# RTI_SMS_LITE_TIFS_WDT_RTI_44135000h register map
Vendor: Texas Instruments
Peripheral module from a debugger description file (folder am62L).
Registers are 32-bit, read-write, reset 0x0 unless marked. A register's access mark holds for its fields unless they carry their own. Offsets are as the file gives them; lines under a group give offsets from that group; [hi:lo] are bit positions; {n}, {i} and the like mark numbered series; 'fields as' and 'values as' point back to an identical list; <NAME> marks a mode.

## SMS_LITE_TIFS_WDT_RTI
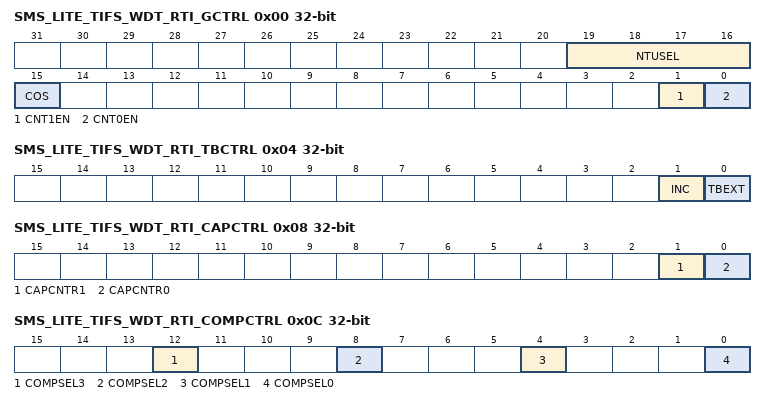
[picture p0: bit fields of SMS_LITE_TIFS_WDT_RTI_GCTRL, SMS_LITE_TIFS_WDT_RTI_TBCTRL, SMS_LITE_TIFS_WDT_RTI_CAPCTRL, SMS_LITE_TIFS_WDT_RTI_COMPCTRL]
0x00 SMS_LITE_TIFS_WDT_RTI_GCTRL
  [19:16] NTUSEL — These bits determine which NTU input signal is used as external timebase. There are up to four inputs supported with four valid selection combinations. Any invalid selection value written to the NTUSEL bit-field will result in a TIED LOW being used as the NTU signal. The NTU signal will also be TIED LOW in case of a single-bit flip as it will result in an invalid combination of NTUSEL. User and privilege mode (read): 0000 = NTU0 0101 = NTU1 1010 = NTU2 1111 = NTU3 other = tied to '0' Privilege mode (write): 0000 = NTU0 0101 = NTU1 1010 = NTU2 1111 = NTU3 other = tied to '0' Reset Source: sms_custom_rst_mod_g_rst_n
  [15] COS — This bit determines if both counters are stopped when the device goes into debug mode or if they continue counting. User and privilege mode (read): 0 = counters are stopped while in debug mode 1 = counters are running while in debug mode Privilege mode (write): 0 = stop counters in debug mode 1 = continue counting in debug mode Reset Source: sms_custom_rst_mod_g_rst_n
  [1] CNT1EN — The CNT1EN bit starts and stops the operation of counter block 1 (UC1 and FRC1). User and privilege mode (read): 0 = counters are stopped 1 = counters are running Privilege mode (write): 0 = stop counters 1 = start counters Reset Source: sms_custom_rst_mod_g_rst_n
  [0] CNT0EN — The CNT0EN bit starts and stops the operation of counter block 0 (UC0 and FRC0). User and privilege mode (read): 0 = counters are stopped 1 = counters are running Privilege mode (write): 0 = stop counters 1 = start counters Reset Source: sms_custom_rst_mod_g_rst_n
0x04 SMS_LITE_TIFS_WDT_RTI_TBCTRL
  [1] INC — This bit determines wether the Free Running Counter 0 is automatically incremented if a failing clock on the NTUx signal is detected. User and privilege mode (read): 0 = FRC0 will not be incremented 1 = FRC0 will be incremented Privilege mode (write): 0 = Do not increment FRC0 on failing external clock 1 = Increment FRC0 on failing external clock Reset Source: sms_custom_rst_mod_g_rst_n
  [0] TBEXT — The Timebase External bit selects whether the Free Running Counter 0 is clocked by the internal Up Counter 0 or from the external signal NTUx. Since setting the TBEXT bit to 1 resets Up Counter 0, Free Running Counter 0 will not be incremented in this occurence. The only source which is able to increment Free Running Counter 0 is NTUx. When the Timebase Supervisor circuit detects a missing clockedge, then the TBEXT bit is reset. The selection if the external signal should be used, can only be done by software. User and privilege mode (read): 0 = UC0 clocks FRC0 1 = NTUx clocks FRC0 Privilege mode (write): 0 = MUX is switched to internal UC0 clocking scheme 1 = MUX is switched to external NTUx clocking scheme Reset Source: sms_custom_rst_mod_g_rst_n
0x08 SMS_LITE_TIFS_WDT_RTI_CAPCTRL
  [1] CAPCNTR1 — This bit determines, which external interrupt source triggers a capture event of both UC1 and FRC1. User and privilege mode (read): 0 = capture event is triggered by Capture Event Source 0 1 = capture event is triggered by Capture Event Source 1 Privilege mode (write): 0 = enable capture event triggered by Capture Event Source 0 1 = enable capture event triggered by Capture Event Source 1 Reset Source: sms_custom_rst_mod_g_rst_n
  [0] CAPCNTR0 — This bit determines, which external interrupt source triggers a capture event of both UC0 and FRC0. User and privilege mode (read): 0 = capture event is triggered by Capture Event Source 0 1 = capture event is triggered by Capture Event Source 1 Privilege mode (write): 0 = enable capture event triggered by Capture Event Source 0 1 = enable capture event triggered by Capture Event Source 1 Reset Source: sms_custom_rst_mod_g_rst_n
0x0C SMS_LITE_TIFS_WDT_RTI_COMPCTRL
  [12] COMPSEL3 — This bit determines the counter with which the compare value hold in compare register 3 is compared. User and privilege mode (read): 0 = value will be compared with FRC 0 1 = value will be compared with FRC 1 Privilege mode (write): 0 = enable compare with FRC 0 1 = enable compare with FRC 1 Reset Source: sms_custom_rst_mod_g_rst_n
  [8] COMPSEL2 — This bit determines the counter with which the compare value hold in compare register 2 is compared. User and privilege mode (read): 0 = value will be compared with FRC 0 1 = value will be compared with FRC 1 Privilege mode (write): 0 = enable compare with FRC 0 1 = enable compare with FRC 1 Reset Source: sms_custom_rst_mod_g_rst_n
  [4] COMPSEL1 — This bit determines the counter with which the compare value hold in compare register 1 is compared.User and privilege mode (read): 0 = value will be compared with FRC 0 1 = value will be compared with FRC 1 Privilege mode (write): 0 = enable compare with FRC 0 1 = enable compare with FRC 1 Reset Source: sms_custom_rst_mod_g_rst_n
  [0] COMPSEL0 — This bit determines the counter with which the compare value hold in compare register 0 is compared. User and privilege mode (read): 0 = value will be compared with FRC 0 1 = value will be compared with FRC 1 Privilege mode (write): 0 = enable compare with FRC 0 1 = enable compare with FRC 1 Reset Source: sms_custom_rst_mod_g_rst_n
0x10 SMS_LITE_TIFS_WDT_RTI_FRC0
  [31:0] FRC0 — This registers holds the current value of the Free Running Counter 0 and will be updated continuously. User and privilege mode (read): current value of the counter Privilege mode (write): The counter can be preset by Writing to this register. The counter increments then from this written value upwards. Note: Presetting counters If counters have to be preset, they have to be stopped from counting in the RTIGCTRL register in order to ensure consistency between RTIUC0 and RTIFRC0. Reset Source: sms_custom_rst_mod_g_rst_n
0x14 SMS_LITE_TIFS_WDT_RTI_UC0
  [31:0] UC0 — This registers holds the current value of the Up Counter 0 and prescales the RTI clock. It will be only updated by a previous read of Free Running Counter 0. This gives effectively a 64 bit read of both counters, without having the problem of a counter being updated between two consecutive reads on Up Counter 0 and Free Running Counter 0. User and privilege mode (read): value of the counter when the Free Running Counter 0 was read Privilege mode (write): the counter can be preset by Writing to this register. The counter increments then from this written value upwards. Note: Presetting counters If counters have to be preset, they have to be stopped from counting in the RTIGCTRL register in order to ensure consistency between RTIUC0 and RTIFRC0. Note: Preset value concern If the preset value is bigger than the compare value stored in register RTICPUC0 then it can take a long time until a compare matches, since RTIUC0 has to count up until it overflows. Reset Source: sms_custom_rst_mod_g_rst_n
0x18 SMS_LITE_TIFS_WDT_RTI_CPUC0
  [31:0] CPUC0 — This registers holds the compare value, which is compared with the Up Counter 0. When the compare matches, Free Running counter 0 is incremented. The Up Counter is set to zero when the counter value matches the CPUC0 value. The value set in this prescales the RTI clock. If CPUC0 = 0: fFRC0 = R-----T---I---C----L----K-- 232 If CPUC0 0: fFRC0 = ----R----T----I--C-----L---K------- CPUC0 + 1 User and privilege mode (read): current compare value Privilege mode (write when TBEXT = 0): the compare value is updated Privilege mode (write when TBEXT = 1): the compare value is not changed Reset Source: sms_custom_rst_mod_g_rst_n
0x20 SMS_LITE_TIFS_WDT_RTI_CAFRC0 ro
  [31:0] CAFRC0 — This registers captures the current value of the Free Running Counter 0 when a event occurs, controlled by the external capture control block. User and privilege mode (read): value of Free Running Counter 0 on a capture event Reset Source: sms_custom_rst_mod_g_rst_n
0x24 SMS_LITE_TIFS_WDT_RTI_CAUC0 ro
  [31:0] CAUC0 — This registers captures the current value of the Up Counter 0 when a event occurs, controlled by the external capture control block. The read sequence has to be the same as with Up Counter 0 and Free Running Counter 0. So the RTICAFRC0 register has to be read first, before the RTICAUC0 register is read. This sequence ensures that the value of the RTICAUC0 register is the corresponding value to the RTICAFRC0 register, even if another capture event happens in between the two reads. User and privilege mode (read): value of Up Counter 0 on a capture event Reset Source: sms_custom_rst_mod_g_rst_n
0x30 SMS_LITE_TIFS_WDT_RTI_FRC1
  [31:0] FRC1 — This registers holds the current value of the Free Running Counter 1 and will be updated continuously. User and privilege mode (read): current value of the counter Privilege mode (write): the counter can be preset by Writing to this register. The counter increments then from this written value upwards. Note: Presetting counters If counters have to be preset, they have to be stopped from counting in the RTIGCTRL register in order to ensure consistency between UC1 and FRC1. Reset Source: sms_custom_rst_mod_g_rst_n
0x34 SMS_LITE_TIFS_WDT_RTI_UC1
  [31:0] UC1 — This registers holds the current value of the Up Counter 1 and prescales the RTI clock. It will be only updated by a previous read of Free Running Counter 1. This gives effectively a 64 bit read of both counters, without having the problem of a counter being updated between two consecutive reads on Up Counter 1 and Free Running Counter 1. User and privilege mode (read): value of the counter when the Free Running Counter 1 was read Privilege mode (write): the counter can be preset by Writing to this register. The counter increments then from this written value upwards. Note: Presetting counters If counters have to be preset, they have to be disabled in the RTIGCTRL register in order to ensure consistency between UC1 and FRC1. Note: Preset value concern If the preset value is bigger than the compare value stored in register RTICPUC1 then it can take a long time until a compare matches, since UC1 has to count up until it overflows. Reset Source: sms_custom_rst_mod_g_rst_n
0x38 SMS_LITE_TIFS_WDT_RTI_CPUC1
  [31:0] CPUC1 — This registers holds the compare value, which is compared with the Up Counter 1. When the compare matches, Free Running Counter 1 is incremented. The Up Counter is set to zero when the counter value matches the CPUC1 value. The value set in this prescales the RTI clock. If CPUC1 = 0: fFRC1 = R-----T---I---C----L----K-- 232 If CPUC1 0: fFRC1 = ----R----T----I--C-----L---K------- CPUC1 + 1 User and privilege mode (read): current compare value Privilege mode (write): the compare value is updated Reset Source: sms_custom_rst_mod_g_rst_n
0x40 SMS_LITE_TIFS_WDT_RTI_CAFRC1 ro
  [31:0] CAFRC1 — This registers captures the current value of the Free Running Counter 1 when a event occurs, controlled by the external capture control block. User and privilege mode (read): value of Free Running Counter 1 on a capture event Reset Source: sms_custom_rst_mod_g_rst_n
0x44 SMS_LITE_TIFS_WDT_RTI_CAUC1 ro
  [31:0] CAUC1 — This registers captures the current value of the Up Counter 1 when a event occurs, controlled by the external capture control block. The read sequence has to be the same as with Up Counter 1 and Free Running Counter 1. So the RTICAFRC1 register has to be read first, before the RTICAUC1 register is read. This sequence ensures that the value of the RTICAUC0 register is the corresponding value to the RTICAFRC0 register, even if another capture event happens in between the two reads. User and privilege mode (read): value of Up Counter 1 on a capture event Reset Source: sms_custom_rst_mod_g_rst_n
{0x50+8i} SMS_LITE_TIFS_WDT_RTI_COMP{i} (i=0..3)
  [31:0] COMP{i} — This registers holds a compare value, which is compared with the counter selected in the compare control logic. If the Free Running Counter matches the compare value, an interrupt is flagged. With this register it is also possible to initiate a DMA request. User and privilege mode (read): current compare value Privilege mode (write): update of the compare register with a new compare value Note: Reset behavior A reset does not generate a compare match, since the compare logic will only be active, when the associated counter block is enabled. Reset Source: sms_custom_rst_mod_g_rst_n
{0x54+8i} SMS_LITE_TIFS_WDT_RTI_UDCP{i} (i=0..3)
  [31:0] UDCP{i} — This registers holds a value, which is added to the value in the compare {i} register each time a compare matches. This gives the possibility to generate periodic interrupts without software intervention. User and privilege mode (read): value to be added to the compare {i} register on the next compare match Privilege mode (write): new update value Reset Source: sms_custom_rst_mod_g_rst_n
0x70 SMS_LITE_TIFS_WDT_RTI_TBLCOMP
  [31:0] TBLCOMP — This value determines when the edge detection circuit starts monitoring the NTUx signal. It will be compared with Up Counter 0. User and privilege mode (read): current compare value Privilege mode (write when TBEXT = 0): the compare value is updated Privilege mode (write when TBEXT = 1): the compare value is not changed Note: Reset behavior A reset does not generate a compare match. Reset Source: sms_custom_rst_mod_g_rst_n
0x74 SMS_LITE_TIFS_WDT_RTI_TBHCOMP
  [31:0] TBHCOMP — This value determines when the edge detection circuit will stop monitoring the NTUx signal. It will be compared with Up Counter 0. RTITBHCOMP has to be less than RTICPUC0, since RTIUC0 will be reset when RTICPUC0 is reached. Example: The NTUx edge detection circuit should be active +/- 10 RTICLK cycles around RTICPUC0. RTICPUC0 = 0x00000050 RTITBLCOMP = 0x000046 RTITBHCOMP = 0x00000009 User and privilege mode (read): current compare value Privilege mode (write when TBEXT = 0): the compare value is updated Privilege mode (write when TBEXT = 1): the compare value is not changed Note: Reset behavior A reset does not generate a compare match. Reset Source: sms_custom_rst_mod_g_rst_n
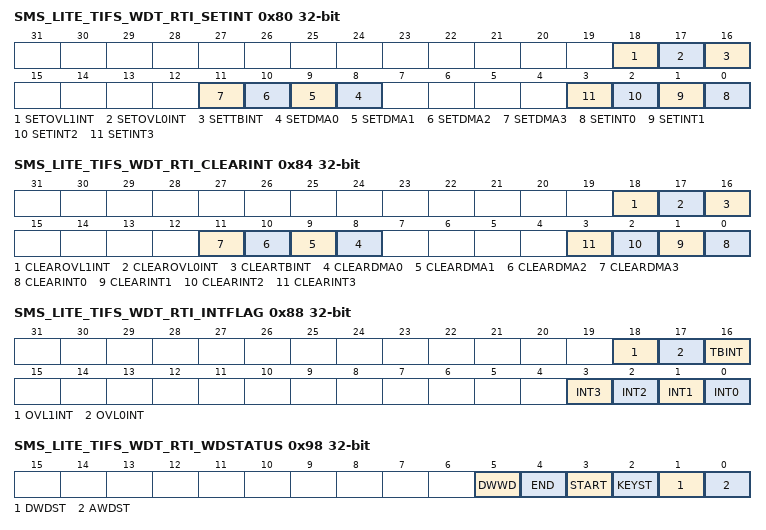
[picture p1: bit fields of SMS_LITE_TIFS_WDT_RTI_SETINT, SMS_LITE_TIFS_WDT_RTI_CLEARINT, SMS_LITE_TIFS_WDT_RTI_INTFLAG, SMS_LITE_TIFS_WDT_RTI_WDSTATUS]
0x80 SMS_LITE_TIFS_WDT_RTI_SETINT access not given
  [18] SETOVL1INT — User and privilege mode (read): 0 = interrupt is disabled 1 = interrupt is enabled Privilege mode (write): 0 = leaves the corresponding bit unchanged 1 = enable interrupt Reset Source: sms_custom_rst_mod_g_rst_n (access R/W1TS)
  [17] SETOVL0INT — User and privilege mode (read): 0 = interrupt is disabled 1 = interrupt is enabled Privilege mode (write): 0 = leaves the corresponding bit unchanged 1 = enable interrupt Reset Source: sms_custom_rst_mod_g_rst_n (access R/W1TS)
  [16] SETTBINT — User and privilege mode (read): 0 = interrupt is disabled 1 = interrupt is enabled Privilege mode (write): 0 = leaves the corresponding bit unchanged 1 = enable interrupt Reset Source: sms_custom_rst_mod_g_rst_n (access R/W1TS)
  [n+8] SETDMA{n} (n=0..3) — User and privilege mode (read): 0 = DMA request is disabled 1 = DMA request is enabled Privilege mode (write): 0 = leaves the corresponding bit unchanged 1 = enable DMA request Reset Source: sms_custom_rst_mod_g_rst_n (access R/W1TS)
  [n] SETINT{n} (n=0..3) — User and privilege mode (read): 0 = interrupt is disabled 1 = interrupt is enabled Privilege mode (write): 0 = leaves the corresponding bit unchanged 1 = enable interrupt Reset Source: sms_custom_rst_mod_g_rst_n (access R/W1TS)
0x84 SMS_LITE_TIFS_WDT_RTI_CLEARINT access not given
  [18] CLEAROVL1INT — User and privilege mode (read): 0 = interrupt is disabled 1 = interrupt is enabled Privilege mode (write): 0 = leaves the corresponding bit unchanged 1 = disable interrupt Reset Source: sms_custom_rst_mod_g_rst_n (access R/W1TC)
  [17] CLEAROVL0INT — User and privilege mode (read): 0 = interrupt is disabled 1 = interrupt is enabled Privilege mode (write): 0 = leaves the corresponding bit unchanged 1 = disable interrupt Reset Source: sms_custom_rst_mod_g_rst_n (access R/W1TC)
  [16] CLEARTBINT — User and privilege mode (read): 0 = interrupt is disabled 1 = interrupt is enabled Privilege mode (write): 0 = leaves the corresponding bit unchanged 1 = disable interrupt Reset Source: sms_custom_rst_mod_g_rst_n (access R/W1TC)
  [n+8] CLEARDMA{n} (n=0..3) — User and privilege mode (read): 0 = DMA request is disabled 1 = DMA request is enabled Privilege mode (write): 0 = leaves the corresponding bit unchanged 1 = disable DMA request Reset Source: sms_custom_rst_mod_g_rst_n (access R/W1TC)
  [n] CLEARINT{n} (n=0..3) — User and privilege mode (read): 0 = interrupt is disabled 1 = interrupt is enabled Privilege mode (write): 0 = leaves the corresponding bit unchanged 1 = disable interrupt Reset Source: sms_custom_rst_mod_g_rst_n (access R/W1TC)
0x88 SMS_LITE_TIFS_WDT_RTI_INTFLAG access not given
  [18] OVL1INT — User and privilege mode (read): determines if an interrupt is pending 0 = no interrupt pending 1 = interrupt pending Privilege mode (write): 0 = leaves the bit unchanged 1 = set the bit to 0 Reset Source: sms_custom_rst_mod_g_rst_n (access R/W1TC)
  [17] OVL0INT — User and privilege mode (read): determines if an interrupt is pending 0 = no interrupt pending 1 = interrupt pending Privilege mode (write): 0 = leaves the bit unchanged 1 = set the bit to 0 Reset Source: sms_custom_rst_mod_g_rst_n (access R/W1TC)
  [16] TBINT — User and privilege mode (read): this flag is set when the TBEXT bit is cleared by detection of a missing external clockedge. It will not be set by clearing TBEXT by software. determines if an interrupt is pending 0 = no interrupt pending 1 = interrupt pending Privilege mode (write): 0 = leaves the bit unchanged 1 = set the bit to 0 Reset Source: sms_custom_rst_mod_g_rst_n (access R/W1TC)
  [n] INT{n} (n=0..3) — User and privilege mode (read): determines if a interrupt is pending 0 = no interrupt pending 1 = interrupt pending Privilege mode (write): 0 = leaves the bit unchanged 1 = set the bit to 0 Reset Source: sms_custom_rst_mod_g_rst_n (access R/W1TC)
0x90 SMS_LITE_TIFS_WDT_RTI_DWDCTRL reset 0x5312ACED
  [31:0] DWDCTRL — User and priviledge mode (read): 0x5312ACED = DWD counter is disabled. This is the default value. 0xA98559DA = DWD counter is enabled Any other value = DWD counter state is unchanged (enabled or disabled) Priviledge mode (write): 0xA98559DA = DWD counter is enabled Any other value = State of DWD counter is unchanged (stays enabled or disabled) Note: One-Write Functionality of DWDCTRL Register The RTIDWDCTRL register implements a one-write functionality, such that the application cannot write to this registermore than once. Writing the default value will not enable the watchdog as described above. Writing the enable value will start the watchdog counters. A write to RTIDWDCTRL will only be enabled after a system reset again. Reset Source: sms_custom_rst_mod_g_rst_n
0x94 SMS_LITE_TIFS_WDT_RTI_DWDPRLD reset 0xFFF
  [11:0] DWDPRLD — User and priviledge mode (read): A read from this register in any CPU mode returns the current preload value. Priviledge mode (write): If the DWD is always enabled after reset is released: The DWD starts counting down from the reset value of the counter, that is, 0x002DFFFF. The application can configure the DWD preload register any time before this down counter expires. When the application services the DWD, the preload register contents are copied left- justified into the DWD down counter and it starts counting down from that value. If the DWD is implemented such that the down counter is enabled by software: The DWD preload register can be configured only when the DWD is disabled. Therefore, the application can only configure the DWD preload register before it enables the DWD down counter. The expiration time of the DWD Down Counter can be determined with following equation: texp = (RTIDWDPRLD+1) x 213 / RTICLK1 where: RTIDWDPRLD = 0...4095 Reset Source: sms_custom_rst_mod_g_rst_n
0x98 SMS_LITE_TIFS_WDT_RTI_WDSTATUS access not given
  [5] DWWD — This bit denotes whether the time-window defined by the windowed watchdog configuration has been violated, or if a wrong key or key sequence was written to service the watchdog. User and priviledge mode (read): 0 = no time-window violation has occurred. 1 = a time-window violation has occurred. The watchdog will generate either a system reset or a non-maskable interrupt to the CPU in this case. Priviledge mode (write): 0 = leaves the current value unchanged. 1 = clears the bit to 0. This will also clear all other status flags in the RTIWDSTATUS reg- ister except for the AWD ST flag. Clearing of the status flags will deassert the non- maskable interrupt generated due to violation of the DWWD. Reset Source: sms_custom_rst_mod_g_rst_n (access R/W1TC)
  [4] END — This bit denotes whether the end-time defined by the windowed watchdog configuration has been violated. This bit is effectively a copy of the DWD ST status flag. User and priviledge mode (read): 0 = no end-time window violation has occurred. 1 = the end-time defined by the windowed watchdog configuration has been violated. Priviledge mode (write): 0 = leaves the current value unchanged. 1 = clears the bit to 0. Reset Source: sms_custom_rst_mod_g_rst_n (access R/W1TC)
  [3] START — This bit denotes whether the start-time defined by the windowed watchdog configuration has been violated. This indicates that the WWD was serviced before the service window was opened. User and priviledge mode (read): 0 = no start-time window violation has occurred. 1 = the start-time defined by the windowed watchdog configuration has been violated. Priviledge mode (write): 0 = leaves the current value unchanged. 1 = clears the bit to 0. Reset Source: sms_custom_rst_mod_g_rst_n (access R/W1TC)
  [2] KEYST — This bit denotes a reset generated by a wrong key or a wrong key-sequence written to the RTIWDKEY register. User and priviledge mode (read): 0 = no wrong key or key-sequence written 1 = wrong key or key-sequence written to RTIWDKEY register Priviledge mode (write): 0 = leaves the current value unchanged 1 = clears the bit to 0 Reset Source: sms_custom_rst_mod_g_rst_n (access R/W1TC)
  [1] DWDST — status flag and is maintained for compatibility reasons. User and priviledge mode (read): 0 = DWD timeout period not expired 1 = DWD timeout period has expired Priviledge mode (write): 0 = leaves the current value unchanged 1 = clears the bit to 0 Reset Source: sms_custom_rst_mod_g_rst_n (access R/W1TC)
  [0] AWDST — User and priviledge mode (read): 0 = AWD pin 0 > 1 threshold not exceeded 1 = AWD pin 0 > 1 threshold exceeded Priviledge mode (write): 0 = leaves the current value unchanged 1 = clears the bit to 0 Reset Source: sms_custom_rst_mod_g_rst_n (access R/W1TC)
0x9C SMS_LITE_TIFS_WDT_RTI_WDKEY reset 0xA35C
  [15:0] WDKEY — User and privilege mode reads are indeterminate. Privilege mode (write): A write of 0xE51A followed by 0xA35C in two separate write operations defines the Key Sequence and discharges the watchdog capacitor. This also causes the upper 12 bits of the DWD down counter to be reloaded with the contents of the DWD preload register and the lower 13 bits to become all 1's. Writing any other value causes a digital watchdog reset, as shown in Table 1-3. Note: Register write access time precaution The user has to take into account that the write to the register takes 3 VCLK cycle. This needs to be considered for the AWD/DWD expiration calculation. Table 2. Example of a WDKEY sequence Value written to Step WDKEY Result 1 0x0A35C No Action 2 0x0A35C No Action 3 0x0E51A WDKEY is enabled for reset by next 0x0A35C 4 0x0E51A WDKEY is enabled for reset by next 0x0A35C 5 0x0E51A WDKEY is enabled for reset by next 0x0A35C 6 0x0A35C Watchdog is reset 7 0x0A35C No Action 8 0x0E51A WDKEY is enabled for reset by next 0x0A35C 9 0x0A35C Watchdog is reset 10 0x0E51A WDKEY is enabled for reset by next 0x0A35C 11 0x02345 System reset; incorrect value written to WDKEY Reset Source: sms_custom_rst_mod_g_rst_n
0xA0 SMS_LITE_TIFS_WDT_RTI_DWDCNTR ro reset 0x3FF
  [24:0] DWDCNTR — The value of the DWDCNTR after a system reset is 0x002D_FFFF. When the DWD is enabled and the DWD counter starts counting down from this value with an RTICLK1 time base of 3MHz, a watchdog reset will be generated in 1 second. User and privilege mode (read): Reads return the current counter value. Privilege mode (write): Writes don't have an effect. Reset Source: sms_custom_rst_mod_g_rst_n
0xA4 SMS_LITE_TIFS_WDT_RTI_WWDRXNCTRL reset 0x5
  [3:0] WWDRXN — User and privilege mode (read), privileged mode (write): 0x5 = This is the default value. The windowed watchdog will cause a reset if the watchdog is serviced outside the time window defined by the configuration, or if the watchdog is not serviced at all. 0xA = The windowed watchdog will generate a non-maskable interrupt to the CPU if the watchdog is serviced outside the time window defined by the configuration, or if the watchdog is not serviced at all. Writing any other value will cause a system reset if the watchdog is serviced outside the time window defined by the configuration, or if the watchdog is not serviced at all. Note: Configuration of DWWD Reaction The DWWD reaction can be selected by the application even when the DWWD counter is already enabled. If a change to the WWDRXN is made before the watchdog service window is opened, then the change in the configuration takes effect immediately. If a change to the WWDRXN is made when the watchdog service window is already open, then the change in configuration takes effect only after the watchdog is serviced. Reset Source: sms_custom_rst_mod_g_rst_n
0xA8 SMS_LITE_TIFS_WDT_RTI_WWDSIZECTRL reset 0x5
  [31:0] WWDSIZE — User and privilege mode (read), privileged mode (write): Table 3. Windowed Watchdog Window Size Configuration Value written to WWDSIZE Window Size 0x00000005 100% (The functionality is the same as the standard time-out digital watchdog.) 0x00000050 50% 0x00000500 25% 0x00005000 12.5% 0x00050000 6.25% 0x00500000 3.125% Any other 3.125% value Note: Incorrect value being written to watchdog window size control register If an incorerct value is written to the WWDSIZE field, or if a system disturbance causes the WWDSIZE field to have a value other than 0x5, 0x50, 0x500, 0x5000, 0x50000, or 0x500000, then the window size will be configured to be 3.125%. This increases the chances of getting a reset due to the windowed watchdog, which enables the system to handle the cause for the incorrect configuration. Note: Configuration of DWWD Window Size The DWWD window size can be selected by the application even when the DWWD counter is already enabled. If a change to the WWDSIZE is made before the watchdog service window is opened, then the change in the configuration takes effect immediately. If a change to the WWDSIZE is made when the watchdog service window is already open, then the change in configuration takes effect only after the watchdog is serviced. Reset Source: sms_custom_rst_mod_g_rst_n
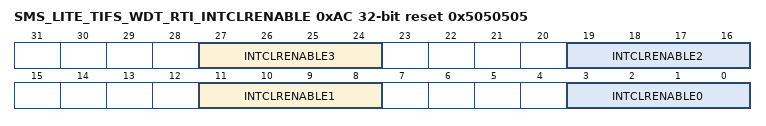
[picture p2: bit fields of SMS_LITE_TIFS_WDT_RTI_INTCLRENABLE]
0xAC SMS_LITE_TIFS_WDT_RTI_INTCLRENABLE reset 0x5050505
  [27:24] INTCLRENABLE3 — Enables the auto-clear functionality on the compare 3 interrupt. User and Privileged mode (read): 0x5 = Auto-clear for compare 3 interrupt is disabled. Any other value = Auto-clear for compare 3 interrupt is enabled. Privileged mode (write): 0x5 = Disables the auto-clear functionality on the compare 3 interrupt. Any other value = Enables the auto-clear functionality on the compare 3 interrupt. Reset Source: sms_custom_rst_mod_g_rst_n
  [19:16] INTCLRENABLE2 — Enables the auto-clear functionality on the compare 2 interrupt. User and Privileged mode (read): 0x5 = Auto-clear for compare 2 interrupt is disabled. Any other value = Auto-clear for compare 2 interrupt is enabled. Privileged mode (write): 0x5 = Disables the auto-clear functionality on the compare 2 interrupt. Any other value = Enables the auto-clear functionality on the compare 2 interrupt. Reset Source: sms_custom_rst_mod_g_rst_n
  [11:8] INTCLRENABLE1 — Enables the auto-clear functionality on the compare 1 interrupt. User and Privileged mode (read): 0x5 = Auto-clear for compare 1 interrupt is disabled. Any other value = Auto-clear for compare 1 interrupt is enabled. Privileged mode (write): 0x5 = Disables the auto-clear functionality on the compare 1 interrupt. Any other value = Enables the auto-clear functionality on the compare 1 interrupt. Reset Source: sms_custom_rst_mod_g_rst_n
  [3:0] INTCLRENABLE0 — Enables the auto-clear functionality on the compare 0 interrupt. User and Privileged mode (read): 0x5 = Auto-clear for compare 0 interrupt is disabled. Any other value = Auto-clear for compare 0 interrupt is enabled. Privileged mode (write): 0x5 = Disables the auto-clear functionality on the compare 0 interrupt. Any other value = Enables the auto-clear functionality on the compare 0 interrupt. Note: Hook-up of Compare Interrupt to a device pin The RTI module generates up to 4 compare interrupts. The connection between one or more of these compare interrupt(s) to a device pin is completely device-dependent. Refer to the device datasheet to identify the actual pin(s) that connects to the compare interrupt(s). Reset Source: sms_custom_rst_mod_g_rst_n
{0xB0+4i} SMS_LITE_TIFS_WDT_RTI_COMP{i}CLR (i=0..3)
  [31:0] COMP{i}CLR — This registers holds a compare value, which is compared with the counter selected in the compare control logic. If the Free Running Counter matches the compare value, the compare {i} interrupt or DMA request line is cleared. User and privilege mode (read): current compare value Privilege mode (write): update of the compare register with a new compare value Note: Reset behavior A reset does not generate a compare match, since the compare logic will only be active, when the associated counter block is enabled. Reset Source: sms_custom_rst_mod_g_rst_n
